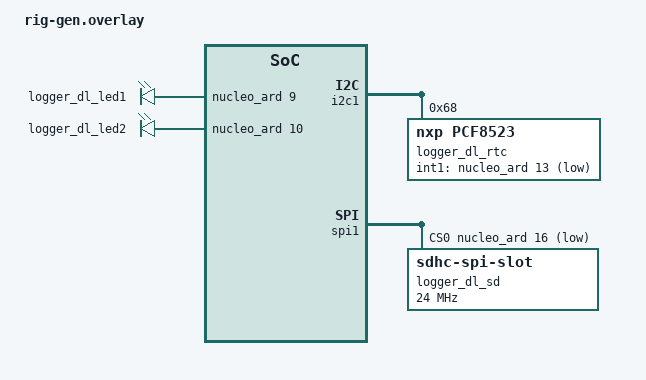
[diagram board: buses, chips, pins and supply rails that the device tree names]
/* generated by rigc — do not edit; the rig file is the source of truth
 * rig: pilot_variants  board: nucleo_f401re/stm32f401xe/rig
 */

&i2c1 {
	logger_dl_rtc: rtc@68 {
		compatible = "nxp,pcf8523";
		alarms-count = <1>;
		battery-switch-over = "standard";
		reg = <0x68>;
		int1-gpios = <&nucleo_ard 13 0x11>;	/* D7 */
		status = "okay";
	};
};

&spi1 {
	cs-gpios = <&nucleo_ard 16 1 /* ACTIVE_LOW */>;
	logger_dl_sd: sdhc@0 {
		compatible = "zephyr,sdhc-spi-slot";
		spi-max-frequency = <24000000>;
		reg = <0>;
		status = "okay";
		sdmmc {
			compatible = "zephyr,sdmmc-disk";
			disk-name = "SD";
			status = "okay";
		};
	};
};

/ {
	gpio_leds: gpio_leds {
		compatible = "gpio-leds";
		logger_dl_led1: logger_dl_led1 {
			label = "logger_dl_led1";
			gpios = <&nucleo_ard 9 0x0>;	/* D3 */
		};
		logger_dl_led2: logger_dl_led2 {
			label = "logger_dl_led2";
			gpios = <&nucleo_ard 10 0x0>;	/* D4 */
		};
	};
};
